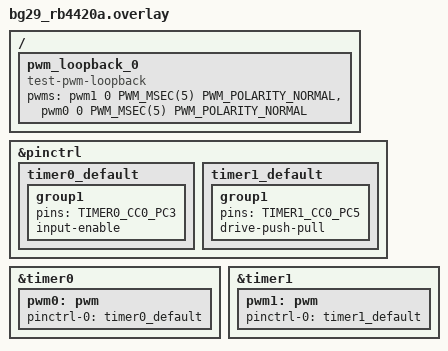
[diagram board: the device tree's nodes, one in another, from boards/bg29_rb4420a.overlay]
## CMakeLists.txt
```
# SPDX-License-Identifier: Apache-2.0

cmake_minimum_required(VERSION 3.28.0)

find_package(Zephyr REQUIRED HINTS $ENV{ZEPHYR_BASE})
project(pwm_loopback)

FILE(GLOB app_sources src/*.c)
target_sources(app PRIVATE ${app_sources})
```

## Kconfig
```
# Copyright 2025 NXP
#
# SPDX-License-Identifier: Apache-2.0

mainmenu "PWM loopback test"

config TEST_PWM_PERIOD_NSEC
	int "Test PWM period in nanoseconds"
	default 100000000

config TEST_PWM_PULSE_NSEC
	int "Test PWM pulse in nanoseconds"
	default 15000000

config TEST_PWM_PERIOD_USEC
	int "Test PWM period in microseconds"
	default 100000

config TEST_PWM_PULSE_USEC
	int "Test PWM pulse in microseconds"
	default 75000

source "Kconfig.zephyr"
```

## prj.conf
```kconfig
CONFIG_ZTEST=y
CONFIG_TEST_USERSPACE=y

CONFIG_PWM=y
CONFIG_PWM_CAPTURE=y
```

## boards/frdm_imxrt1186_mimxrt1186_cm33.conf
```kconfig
CONFIG_TEST_PWM_PERIOD_NSEC=20000000
CONFIG_TEST_PWM_PULSE_NSEC=10000000

CONFIG_TEST_PWM_PERIOD_USEC=20000
CONFIG_TEST_PWM_PULSE_USEC=10000
```

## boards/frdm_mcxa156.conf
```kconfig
# Copyright 2026 NXP
#
# SPDX-License-Identifier: Apache-2.0

# The FlexPWM counter is 16-bit and runs at bus clock / 128 = 750 kHz, so the
# default 100 ms period would need 75000 ticks and be rejected. 20 ms is 15000
# ticks, which also stays inside the 0x7FFF modulo the driver gives a
# capture-only submodule.
CONFIG_TEST_PWM_PERIOD_NSEC=20000000
CONFIG_TEST_PWM_PULSE_NSEC=10000000

CONFIG_TEST_PWM_PERIOD_USEC=20000
CONFIG_TEST_PWM_PULSE_USEC=10000
```

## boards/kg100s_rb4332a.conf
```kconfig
# Copyright (c) 2026 Martin Moya <martin.moya@focus.uy>
# SPDX-License-Identifier: Apache-2.0

# TIMER1 (capture, 16-bit) at 76.8 MHz EM01GRPACLK overflows after ~853 us.
# Use 800 us period so the capture value fits in the 16-bit counter.
CONFIG_TEST_PWM_PERIOD_NSEC=800000
CONFIG_TEST_PWM_PULSE_NSEC=400000
CONFIG_TEST_PWM_PERIOD_USEC=800
CONFIG_TEST_PWM_PULSE_USEC=400
```

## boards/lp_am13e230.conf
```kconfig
# SPDX-FileCopyrightText: 2026 Texas Instruments Incorporated
# SPDX-License-Identifier: Apache-2.0

# AM13e MPU map is still incomplete for userspace ztests; run capture
# cases in supervisor mode (same approach as other boards here).
CONFIG_TEST_USERSPACE=n
```

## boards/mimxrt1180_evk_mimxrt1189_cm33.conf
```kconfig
CONFIG_TEST_PWM_PERIOD_NSEC=10000000
CONFIG_TEST_PWM_PULSE_NSEC=1500000

CONFIG_TEST_PWM_PERIOD_USEC=10000
CONFIG_TEST_PWM_PULSE_USEC=7500
```

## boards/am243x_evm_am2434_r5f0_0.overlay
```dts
/*
 * SPDX-FileCopyrightText: 2026 Texas Instruments Incorporated
 * SPDX-License-Identifier: Apache-2.0
 */

#include <zephyr/dt-bindings/pwm/pwm.h>

/ {
	pwm_loopback_0 {
		compatible = "test-pwm-loopback";
		pwms = <&main_epwm0 0 0 PWM_POLARITY_NORMAL>,
		       <&main_ecap0 0 0 PWM_POLARITY_NORMAL>;
	};
};

&main_epwm0 {
	status = "okay";
};

&main_ecap0 {
	status = "okay";
};
```

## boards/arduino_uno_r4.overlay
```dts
/*
 * Copyright (c) 2025 TOKITA Hiroshi
 *
 * SPDX-License-Identifier: Apache-2.0
 */

#include <zephyr/dt-bindings/pwm/pwm.h>
#include <zephyr/dt-bindings/pwm/ra_pwm.h>

/ {
	pwm_loopback_0 {
		compatible = "test-pwm-loopback";
		/* first index must be a 32-Bit timer */
		pwms = <&pwm0 0 0 PWM_POLARITY_NORMAL>,
		       <&pwm7 0 0 PWM_POLARITY_NORMAL>;
	};
};

&pinctrl {
	pwm0_default: pwm0_default {
		group1 {
			/* GTIOC0A */
			psels = <RA_PSEL(RA_PSEL_GPT1, 1, 7)>;
		};
	};
};

&pwm0 {
	pinctrl-0 = <&pwm0_default>;
	pinctrl-names = "default";
	interrupts = <30 1>, <31 1>;
	interrupt-names = "gtioca", "overflow";
	status = "okay";
};
```

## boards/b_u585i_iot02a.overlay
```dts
/*
 * Copyright (c) 2022 STMicroelectronics
 *
 * SPDX-License-Identifier: Apache-2.0
 */

/ {
	pwm_loopback_0 {
		compatible = "test-pwm-loopback";
		/* first index must be a 32-Bit timer */
		pwms = <&pwm4 1 0 PWM_POLARITY_NORMAL>,
		       <&pwm3 2 0 PWM_POLARITY_NORMAL>;
	};
};
```

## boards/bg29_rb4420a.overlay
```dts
/*
 * Copyright (c) 2025 Silicon Laboratories Inc.
 *
 * SPDX-License-Identifier: Apache-2.0
 */

/* Connections:
 * EXP4 - EXP6: TIMER (PC5) to TIMER (PC3)
 */

/ {
	pwm_loopback_0 {
		compatible = "test-pwm-loopback";
		pwms = <&pwm1 0 PWM_MSEC(5) PWM_POLARITY_NORMAL>,
		       <&pwm0 0 PWM_MSEC(5) PWM_POLARITY_NORMAL>;
	};
};

&pinctrl {
	timer0_default: timer0_default {
		group1 {
			pins = <TIMER0_CC0_PC3>;
			input-enable;
		};
	};

	timer1_default: timer1_default {
		group1 {
			pins = <TIMER1_CC0_PC5>;
			drive-push-pull;
		};
	};
};

&timer0 {
	status = "okay";

	pwm0: pwm {
		pinctrl-0 = <&timer0_default>;
		pinctrl-names = "default";
		status = "okay";
	};
};

&timer1 {
	status = "okay";

	pwm1: pwm {
		pinctrl-0 = <&timer1_default>;
		pinctrl-names = "default";
		status = "okay";
	};
};
```

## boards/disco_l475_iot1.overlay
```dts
/*
 * Copyright (c) 2021 Tilmann Unte
 *
 * SPDX-License-Identifier: Apache-2.0
 */

#include <zephyr/dt-bindings/pwm/pwm.h>

/ {
	pwm_loopback_0 {
		compatible = "test-pwm-loopback";
		/* first index must be a 32-Bit timer */
		pwms = <&pwm2 1 0 PWM_POLARITY_NORMAL>,
		       <&pwm15 1 0 PWM_POLARITY_NORMAL>;
	};
};

/* 32-Bit timers */
&timers2 {
	status = "okay";

	pwm2: pwm {
		pinctrl-0 = <&tim2_ch1_pa5>; /* CN1 D13 */
		pinctrl-names = "default";
		status = "okay";
	};
};

&timers5 {
	status = "okay";

	pwm5: pwm {
		pinctrl-0 = <&tim5_ch1_pa0>; /* CN3 D1 */
		pinctrl-names = "default";
		status = "okay";
	};
};

/* 16-Bit timers */
&timers3 {
	st,prescaler = <255>;
	status = "okay";

	pwm3: pwm {
		pinctrl-0 = <&tim3_ch1_pa6>; /* CN1 D12 */
		pinctrl-names = "default";
		status = "okay";
	};
};

&timers15 {
	st,prescaler = <255>;
	status = "okay";

	pwm15: pwm {
		pinctrl-0 = <&tim15_ch1_pa2>; /* CN1 D10 */
		pinctrl-names = "default";
		status = "okay";
	};
};
```

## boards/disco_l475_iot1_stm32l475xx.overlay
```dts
/*
 * Copyright (c) 2021 Tilmann Unte
 *
 * SPDX-License-Identifier: Apache-2.0
 */

#include <zephyr/dt-bindings/pwm/pwm.h>

/ {
	pwm_loopback_0 {
		compatible = "test-pwm-loopback";
		/* first index must be a 32-Bit timer */
		pwms = <&pwm2 1 0 PWM_POLARITY_NORMAL>,
			<&pwm15 1 0 PWM_POLARITY_NORMAL>;
	};
};

/* 32-Bit timers */
&timers2 {
	status = "okay";
	pwm2: pwm {
		status = "okay";
		pinctrl-0 = <&tim2_ch1_pa5>; /* CN1 D13 */
		pinctrl-names = "default";
	};
};

&timers5 {
	status = "okay";
	pwm5: pwm {
		status = "okay";
		pinctrl-0 = <&tim5_ch1_pa0>; /* CN3 D1 */
		pinctrl-names = "default";
	};
};

/* 16-Bit timers */
&timers3 {
	status = "okay";
	st,prescaler = <255>;
	pwm3: pwm {
		status = "okay";
		pinctrl-0 = <&tim3_ch1_pa6>; /* CN1 D12 */
		pinctrl-names = "default";
	};
};

&timers15 {
	status = "okay";
	st,prescaler = <255>;
	pwm15: pwm {
		status = "okay";
		pinctrl-0 = <&tim15_ch1_pa2>; /* CN1 D10 */
		pinctrl-names = "default";
	};
};
```

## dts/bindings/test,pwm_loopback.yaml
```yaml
#
# Copyright (c) 2020-2021 Vestas Wind Systems A/S
#
# SPDX-License-Identifier: Apache-2.0
#

description: |
    This binding provides resources required to build and run the
    tests/drivers/pwm/pwm_loopback test in Zephyr.

compatible: "test,pwm_loopback"

properties:
    pwms:
        type: phandle-array
        required: true
        description: |
          PWM pins that will be used for generating and capturing a pulse-width
          modulated signal. The pin at the first index will be used for signal
          generation while the pin at the second index will be used for capuring
          the generated signal. The two pins must be physically connected to
          each other.

    capture-pwm-timer-bits:
        type: int
        required: false
        default: 16
        description: |
            Bit width of the pwm capture timer.
            It is used for capture timer accumulation test cases.
```

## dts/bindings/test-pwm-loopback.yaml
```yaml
#
# Copyright (c) 2020-2021 Vestas Wind Systems A/S
#
# SPDX-License-Identifier: Apache-2.0
#

description: |
    This binding provides resources required to build and run the
    tests/drivers/pwm/pwm_loopback test in Zephyr.

compatible: "test-pwm-loopback"

properties:
  pwms:
    type: phandle-array
    required: true
    description: |
      PWM pins that will be used for generating and capturing a pulse-width
      modulated signal. The pin at the first index will be used for signal
      generation while the pin at the second index will be used for capuring
      the generated signal. The two pins must be physically connected to
      each other.
```

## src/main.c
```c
/*
 * Copyright (c) 2020-2021 Vestas Wind Systems A/S
 *
 * SPDX-License-Identifier: Apache-2.0
 */

#include <zephyr/kernel.h>
#include <zephyr/ztest.h>

#include "test_pwm_loopback.h"

static void *pwm_loopback_setup(void)
{
	struct test_pwm in;
	struct test_pwm out;

	get_test_pwms(&out, &in);

	k_object_access_grant(out.dev, k_current_get());
	k_object_access_grant(in.dev, k_current_get());

	return NULL;
}

static void pwm_loopback_after(void *f)
{
	struct test_pwm in;
	struct test_pwm out;
	int err;

	ARG_UNUSED(f);

	get_test_pwms(&out, &in);

	err = pwm_disable_capture(in.dev, in.pwm);
	zassert_equal(err, 0, "failed to disable pwm capture (err %d)", err);
}

ZTEST_SUITE(pwm_loopback, NULL, pwm_loopback_setup, NULL, pwm_loopback_after, NULL);
```

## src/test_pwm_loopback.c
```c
/*
 * Copyright (c) 2020-2021 Vestas Wind Systems A/S
 *
 * SPDX-License-Identifier: Apache-2.0
 */

#include <zephyr/kernel.h>
#include <zephyr/drivers/pwm.h>
#include <zephyr/ztest.h>

#include "test_pwm_loopback.h"

enum test_pwm_unit {
	TEST_PWM_UNIT_NSEC,
	TEST_PWM_UNIT_USEC,
};

void get_test_pwms(struct test_pwm *out, struct test_pwm *in)
{
	/* PWM generator device */
	out->dev = DEVICE_DT_GET(PWM_LOOPBACK_OUT_CTLR);
	out->pwm = PWM_LOOPBACK_OUT_CHANNEL;
	out->flags = PWM_LOOPBACK_OUT_FLAGS;
	zassert_true(device_is_ready(out->dev), "pwm loopback output device is not ready");

	/* PWM capture device */
	in->dev = DEVICE_DT_GET(PWM_LOOPBACK_IN_CTLR);
	in->pwm = PWM_LOOPBACK_IN_CHANNEL;
	in->flags = PWM_LOOPBACK_IN_FLAGS;
	zassert_true(device_is_ready(in->dev), "pwm loopback input device is not ready");
}

static void test_capture(uint32_t period, uint32_t pulse, enum test_pwm_unit unit,
		  pwm_flags_t flags)
{
	struct test_pwm in;
	struct test_pwm out;
	uint64_t period_capture = 0;
	uint64_t pulse_capture = 0;
	k_timeout_t timeout;
	int err = 0;

	get_test_pwms(&out, &in);

	switch (unit) {
	case TEST_PWM_UNIT_NSEC:
		TC_PRINT("Testing PWM capture @ %u/%u nsec\n",
			 pulse, period);
		timeout = K_NSEC(period);
		err = pwm_set(out.dev, out.pwm, period, pulse, out.flags ^=
			      (flags & PWM_POLARITY_MASK));
		break;

	case TEST_PWM_UNIT_USEC:
		TC_PRINT("Testing PWM capture @ %u/%u usec\n",
			 pulse, period);
		timeout = K_USEC(period);
		err = pwm_set(out.dev, out.pwm, PWM_USEC(period),
			      PWM_USEC(pulse), out.flags ^=
			      (flags & PWM_POLARITY_MASK));
		break;

	default:
		TC_PRINT("Unsupported test unit");
		ztest_test_fail();
	}

	zassert_equal(err, 0, "failed to set pwm output (err %d)", err);

	/* Wait for the next period to ensure the new period has taken effect before capturing it.
	 * Some PWM IPs only apply the new period after the current one completes.
	 */
	k_sleep(timeout);

	switch (unit) {
	case TEST_PWM_UNIT_NSEC:
		err = pwm_capture_nsec(in.dev, in.pwm, flags, &period_capture,
				       &pulse_capture, K_NSEC(period * 10));
		break;

	case TEST_PWM_UNIT_USEC:
		err = pwm_capture_usec(in.dev, in.pwm, flags, &period_capture,
				       &pulse_capture, K_USEC(period * 10));
		break;

	default:
		TC_PRINT("Unsupported test unit");
		ztest_test_fail();
	}

	pwm_disable_capture(in.dev, in.pwm);

	if (err == -ENOTSUP) {
		TC_PRINT("capture type not supported\n");
		ztest_test_skip();
	}

	zassert_equal(err, 0, "failed to capture pwm (err %d)", err);

	if (flags & PWM_CAPTURE_TYPE_PERIOD) {
		zassert_within(period_capture, period, period / 100,
			       "period capture off by more than 1%%");
	}

	if (flags & PWM_CAPTURE_TYPE_PULSE) {
		zassert_within(pulse_capture, pulse, pulse / 100,
			       "pulse capture off by more than 1%%");
	}
}

ZTEST_USER(pwm_loopback, test_pulse_capture)
{
	test_capture(CONFIG_TEST_PWM_PERIOD_NSEC, CONFIG_TEST_PWM_PULSE_NSEC,
		     TEST_PWM_UNIT_NSEC,
		     PWM_CAPTURE_TYPE_PULSE | PWM_POLARITY_NORMAL);
	test_capture(CONFIG_TEST_PWM_PERIOD_USEC, CONFIG_TEST_PWM_PULSE_USEC,
		     TEST_PWM_UNIT_USEC,
		     PWM_CAPTURE_TYPE_PULSE | PWM_POLARITY_NORMAL);
}

ZTEST_USER(pwm_loopback, test_pulse_capture_inverted)
{
	test_capture(CONFIG_TEST_PWM_PERIOD_NSEC, CONFIG_TEST_PWM_PULSE_NSEC,
		     TEST_PWM_UNIT_NSEC,
		     PWM_CAPTURE_TYPE_PULSE | PWM_POLARITY_INVERTED);
	test_capture(CONFIG_TEST_PWM_PERIOD_USEC, CONFIG_TEST_PWM_PULSE_USEC,
		     TEST_PWM_UNIT_USEC,
		     PWM_CAPTURE_TYPE_PULSE | PWM_POLARITY_INVERTED);
}

ZTEST_USER(pwm_loopback, test_period_capture)
{
	test_capture(CONFIG_TEST_PWM_PERIOD_NSEC, CONFIG_TEST_PWM_PULSE_NSEC,
		     TEST_PWM_UNIT_NSEC,
		     PWM_CAPTURE_TYPE_PERIOD | PWM_POLARITY_NORMAL);
	test_capture(CONFIG_TEST_PWM_PERIOD_USEC, CONFIG_TEST_PWM_PULSE_USEC,
		     TEST_PWM_UNIT_USEC,
		     PWM_CAPTURE_TYPE_PERIOD | PWM_POLARITY_NORMAL);
}

ZTEST_USER(pwm_loopback, test_period_capture_inverted)
{
	test_capture(CONFIG_TEST_PWM_PERIOD_NSEC, CONFIG_TEST_PWM_PULSE_NSEC,
		     TEST_PWM_UNIT_NSEC,
		     PWM_CAPTURE_TYPE_PERIOD | PWM_POLARITY_INVERTED);
	test_capture(CONFIG_TEST_PWM_PERIOD_USEC, CONFIG_TEST_PWM_PULSE_USEC,
		     TEST_PWM_UNIT_USEC,
		     PWM_CAPTURE_TYPE_PERIOD | PWM_POLARITY_INVERTED);
}

ZTEST_USER(pwm_loopback, test_pulse_and_period_capture)
{
	test_capture(CONFIG_TEST_PWM_PERIOD_NSEC, CONFIG_TEST_PWM_PULSE_NSEC,
		     TEST_PWM_UNIT_NSEC,
		     PWM_CAPTURE_TYPE_BOTH | PWM_POLARITY_NORMAL);
	test_capture(CONFIG_TEST_PWM_PERIOD_USEC, CONFIG_TEST_PWM_PULSE_USEC,
		     TEST_PWM_UNIT_USEC,
		     PWM_CAPTURE_TYPE_BOTH | PWM_POLARITY_NORMAL);
}

ZTEST_USER(pwm_loopback, test_period_shrink_while_running)
{
	struct test_pwm in;
	struct test_pwm out;
	uint32_t long_period = CONFIG_TEST_PWM_PERIOD_USEC;
	/* Floor of 2 keeps short_period / 2 (the pulse width below) from rounding to 0. */
	uint32_t short_period = MAX(long_period / 10, 2);
	uint64_t period_capture = 0;
	uint64_t pulse_capture = 0;
	int err;

	get_test_pwms(&out, &in);

	TC_PRINT("Testing period shrink %u -> %u usec while running\n", long_period, short_period);

	err = pwm_set(out.dev, out.pwm, PWM_USEC(long_period), PWM_USEC(long_period / 2),
		      out.flags);
	zassert_equal(err, 0, "failed to set long pwm period (err %d)", err);

	/*
	 * Let the counter advance well past the shorter period's match value
	 * before shrinking the period. A driver that reprograms the period
	 * without realigning its counter leaves the counter above the new match
	 * value, so the match never fires again and the output stops.
	 */
	k_sleep(K_USEC(long_period * 3 / 4));

	err = pwm_set(out.dev, out.pwm, PWM_USEC(short_period), PWM_USEC(short_period / 2),
		      out.flags);
	zassert_equal(err, 0, "failed to shrink pwm period (err %d)", err);

	/* Allow drivers that only apply a new period at the next period boundary to catch up. */
	k_sleep(K_USEC(long_period));

	err = pwm_capture_usec(in.dev, in.pwm, in.flags | PWM_CAPTURE_TYPE_PERIOD, &period_capture,
			       &pulse_capture, K_USEC(short_period * 10));
	pwm_disable_capture(in.dev, in.pwm);

	if (err == -ENOTSUP) {
		TC_PRINT("period capture not supported\n");
		ztest_test_skip();
	}

	zassert_equal(err, 0, "no pwm output after shrinking the period (err %d)", err);
	zassert_within(period_capture, short_period, MAX(short_period / 100, 1),
		       "period capture off by more than 1%%");
}

ZTEST_USER(pwm_loopback, test_capture_timeout)
{
	struct test_pwm in;
	struct test_pwm out;
	uint32_t period;
	uint32_t pulse;
	int err;

	get_test_pwms(&out, &in);

	err = pwm_set_cycles(out.dev, out.pwm, 100, 0, out.flags);
	zassert_equal(err, 0, "failed to set pwm output (err %d)", err);

	err = pwm_capture_cycles(in.dev, in.pwm, PWM_CAPTURE_TYPE_PULSE,
				 &period, &pulse, K_MSEC(1000));
	if (err == -ENOTSUP) {
		TC_PRINT("Pulse capture not supported, "
			 "trying period capture\n");
		err = pwm_capture_cycles(in.dev, in.pwm,
					 PWM_CAPTURE_TYPE_PERIOD, &period,
					 &pulse, K_MSEC(1000));
		if (err == -ENOTSUP) {
			TC_PRINT("capture type not supported\n");
			ztest_test_skip();
		}
	}

	zassert_equal(err, -EAGAIN, "pwm capture did not timeout (err %d)",
		      err);
}

static void continuous_capture_callback(const struct device *dev,
					uint32_t pwm,
					uint32_t period_cycles,
					uint32_t pulse_cycles,
					int status,
					void *user_data)
{
	struct test_pwm_callback_data *data = user_data;

	if (data->count > data->buffer_len) {
		/* Safe guard in case capture is not disabled */
		return;
	}

	if (status != 0) {
		/* Error occurred */
		data->status = status;
		k_sem_give(&data->sem);
	}

	if (data->pulse_capture) {
		data->buffer[data->count++] = pulse_cycles;
	} else {
		data->buffer[data->count++] = period_cycles;
	}

	if (data->count > data->buffer_len) {
		data->status = 0;
		k_sem_give(&data->sem);
	}
}

ZTEST(pwm_loopback, test_continuous_capture)
{
	struct test_pwm in;
	struct test_pwm out;
	uint32_t buffer[10];
	struct test_pwm_callback_data data = {
		.buffer = buffer,
		.buffer_len = ARRAY_SIZE(buffer),
		.count = 0,
		.pulse_capture = true,
	};
	uint64_t usec = 0;
	int err;
	int i;

	get_test_pwms(&out, &in);

	memset(buffer, 0, sizeof(buffer));
	k_sem_init(&data.sem, 0, 1);

	err = pwm_set(out.dev, out.pwm, PWM_USEC(CONFIG_TEST_PWM_PERIOD_USEC),
		      PWM_USEC(CONFIG_TEST_PWM_PULSE_USEC), out.flags);
	zassert_equal(err, 0, "failed to set pwm output (err %d)", err);

	err = pwm_configure_capture(in.dev, in.pwm,
				    in.flags |
				    PWM_CAPTURE_MODE_CONTINUOUS |
				    PWM_CAPTURE_TYPE_PULSE,
				    continuous_capture_callback, &data);
	if (err == -ENOTSUP) {
		TC_PRINT("Pulse capture not supported, "
			 "trying period capture\n");
		err = pwm_configure_capture(in.dev, in.pwm,
					    in.flags |
					    PWM_CAPTURE_MODE_CONTINUOUS |
					    PWM_CAPTURE_TYPE_PERIOD,
					    continuous_capture_callback, &data);
		if (err == -ENOTSUP) {
			TC_PRINT("capture type not supported\n");
			ztest_test_skip();
		} else {
			zassert_equal(err, 0, "failed to configure pwm input (err %d)",
					err);
			data.pulse_capture = false;
		}
	}

	err = pwm_enable_capture(in.dev, in.pwm);
	zassert_equal(err, 0, "failed to enable pwm capture (err %d)", err);

	err = k_sem_take(&data.sem, K_USEC(CONFIG_TEST_PWM_PERIOD_USEC * data.buffer_len * 10));
	zassert_equal(err, 0, "pwm capture timed out (err %d)", err);
	zassert_equal(data.status, 0, "pwm capture failed (err %d)", err);

	err = pwm_disable_capture(in.dev, in.pwm);
	zassert_equal(err, 0, "failed to disable pwm capture (err %d)", err);

	for (i = 0; i < data.buffer_len; i++) {
		err = pwm_cycles_to_usec(in.dev, in.pwm, buffer[i], &usec);
		zassert_equal(err, 0, "failed to calculate usec (err %d)", err);

		if (data.pulse_capture) {
			zassert_within(usec, CONFIG_TEST_PWM_PULSE_USEC,
						CONFIG_TEST_PWM_PULSE_USEC / 100,
				       "pulse capture off by more than 1%%");
		} else {
			zassert_within(usec, CONFIG_TEST_PWM_PERIOD_USEC,
						CONFIG_TEST_PWM_PERIOD_USEC / 100,
				       "period capture off by more than 1%%");
		}
	}
}

ZTEST(pwm_loopback, test_capture_busy)
{
	struct test_pwm in;
	struct test_pwm out;
	uint32_t buffer[10];
	struct test_pwm_callback_data data = {
		.buffer = buffer,
		.buffer_len = ARRAY_SIZE(buffer),
		.count = 0,
		.pulse_capture = true,
	};
	pwm_flags_t flags = PWM_CAPTURE_MODE_SINGLE |
		PWM_CAPTURE_TYPE_PULSE;
	int err;

	get_test_pwms(&out, &in);

	memset(buffer, 0, sizeof(buffer));
	k_sem_init(&data.sem, 0, 1);

	err = pwm_set_cycles(out.dev, out.pwm, 100, 0, out.flags);
	zassert_equal(err, 0, "failed to set pwm output (err %d)", err);

	err = pwm_configure_capture(in.dev, in.pwm, in.flags | flags,
				    continuous_capture_callback, &data);
	if (err == -ENOTSUP) {
		TC_PRINT("Pulse capture not supported, "
			 "trying period capture\n");
		flags = PWM_CAPTURE_MODE_SINGLE | PWM_CAPTURE_TYPE_PERIOD;
		err = pwm_configure_capture(in.dev, in.pwm, in.flags | flags,
					    continuous_capture_callback, &data);
		if (err == -ENOTSUP) {
			TC_PRINT("capture type not supported\n");
			ztest_test_skip();
		} else {
			zassert_equal(err, 0, "failed to configure pwm input (err %d)",
					err);
			data.pulse_capture = false;
		}
	}

	err = pwm_enable_capture(in.dev, in.pwm);
	zassert_equal(err, 0, "failed to enable pwm capture (err %d)", err);

	err = pwm_configure_capture(in.dev, in.pwm, in.flags | flags,
				    continuous_capture_callback, &data);
	zassert_equal(err, -EBUSY, "pwm capture not busy (err %d)", err);

	err = pwm_enable_capture(in.dev, in.pwm);
	zassert_equal(err, -EBUSY, "pwm capture not busy (err %d)", err);

	err = pwm_disable_capture(in.dev, in.pwm);
	zassert_equal(err, 0, "failed to disable pwm capture (err %d)", err);
}

#if DT_NODE_HAS_PROP(DT_PATH(zephyr_user), pwms)
/*
 * Generate and capture on the same instance. Each captured period then holds
 * exactly one counter rollover, so a wrong rollover length shows up as an exact
 * error instead of hiding inside the 1% tolerance.
 */
ZTEST(pwm_loopback, test_period_capture_same_instance)
{
	const struct pwm_dt_spec out = PWM_DT_SPEC_GET_BY_IDX(DT_PATH(zephyr_user), 0);
	const struct pwm_dt_spec in = PWM_DT_SPEC_GET_BY_IDX(DT_PATH(zephyr_user), 1);
	const uint32_t period = 1000U;
	uint32_t period_capture = 0;
	uint32_t pulse_capture = 0;
	uint64_t period_usec;
	int err;

	zassert_true(pwm_is_ready_dt(&out), "same-instance output device is not ready");
	zassert_true(pwm_is_ready_dt(&in), "same-instance input device is not ready");

	err = pwm_cycles_to_usec(out.dev, out.channel, period, &period_usec);
	zassert_equal(err, 0, "failed to calculate usec (err %d)", err);

	err = pwm_set_cycles(out.dev, out.channel, period, period / 4U, out.flags);
	zassert_equal(err, 0, "failed to set pwm output (err %d)", err);

	k_sleep(K_USEC(period_usec));

	err = pwm_capture_cycles(in.dev, in.channel,
				 in.flags | PWM_CAPTURE_TYPE_PERIOD | PWM_POLARITY_INVERTED,
				 &period_capture, &pulse_capture, K_USEC(period_usec * 10));

	/* Leave the line at a constant inactive level for the tests that follow. */
	(void)pwm_set_cycles(out.dev, out.channel, period, 0, out.flags);

	if (err == -ENOTSUP) {
		TC_PRINT("period capture not supported\n");
		ztest_test_skip();
	}

	zassert_equal(err, 0, "failed to capture pwm (err %d)", err);
	zassert_equal(period_capture, period, "period capture %u cycles, expected %u",
		      period_capture, period);
}
#endif /* DT_NODE_HAS_PROP(DT_PATH(zephyr_user), pwms) */
```

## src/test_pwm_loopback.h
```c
/*
 * Copyright (c) 2020-2021 Vestas Wind Systems A/S
 *
 * SPDX-License-Identifier: Apache-2.0
 */

#ifndef __TEST_PWM_LOOPBACK_H__
#define __TEST_PWM_LOOPBACK_H__

#include <zephyr/kernel.h>
#include <zephyr/drivers/pwm.h>
#include <zephyr/ztest.h>

#define PWM_LOOPBACK_OUT_IDX 0
#define PWM_LOOPBACK_IN_IDX  1

#define PWM_LOOPBACK_NODE DT_INST(0, test_pwm_loopback)

#define PWM_LOOPBACK_OUT_CTLR \
	DT_PWMS_CTLR_BY_IDX(PWM_LOOPBACK_NODE, PWM_LOOPBACK_OUT_IDX)
#define PWM_LOOPBACK_OUT_CHANNEL \
	DT_PWMS_CHANNEL_BY_IDX(PWM_LOOPBACK_NODE, PWM_LOOPBACK_OUT_IDX)
#define PWM_LOOPBACK_OUT_FLAGS \
	DT_PWMS_FLAGS_BY_IDX(PWM_LOOPBACK_NODE, PWM_LOOPBACK_OUT_IDX)

#define PWM_LOOPBACK_IN_CTLR \
	DT_PWMS_CTLR_BY_IDX(PWM_LOOPBACK_NODE, PWM_LOOPBACK_IN_IDX)
#define PWM_LOOPBACK_IN_CHANNEL \
	DT_PWMS_CHANNEL_BY_IDX(PWM_LOOPBACK_NODE, PWM_LOOPBACK_IN_IDX)
#define PWM_LOOPBACK_IN_FLAGS \
	DT_PWMS_FLAGS_BY_IDX(PWM_LOOPBACK_NODE, PWM_LOOPBACK_IN_IDX)

struct test_pwm {
	const struct device *dev;
	uint32_t pwm;
	pwm_flags_t flags;
};

struct test_pwm_callback_data {
	uint32_t *buffer;
	size_t buffer_len;
	size_t count;
	int status;
	struct k_sem sem;
	bool pulse_capture;
};

void get_test_pwms(struct test_pwm *out, struct test_pwm *in);

#endif /* __TEST_PWM_LOOPBACK_H__ */
```
